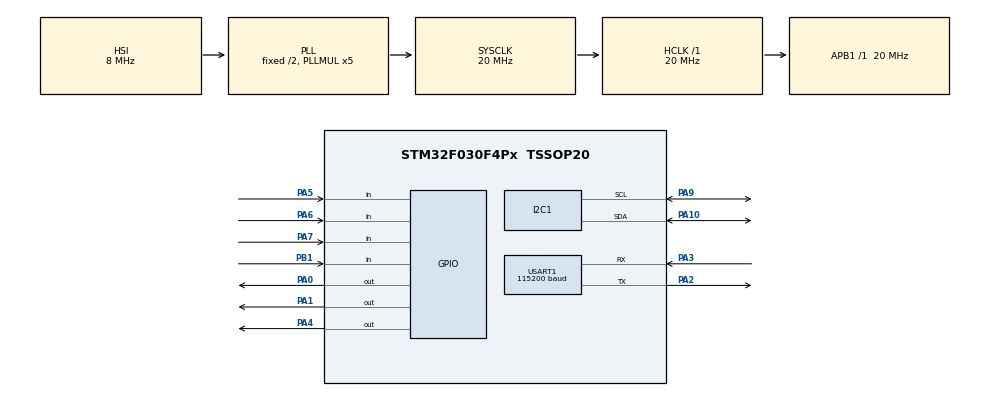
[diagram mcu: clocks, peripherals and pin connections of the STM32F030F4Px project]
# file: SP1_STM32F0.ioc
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I2C1.Timing=0x2000090E
IWDG.Prescaler=IWDG_PRESCALER_8
IWDG.Reload=4000
IWDG.Window=4000
Mcu.Family=STM32F0
Mcu.Name=STM32F030F4Px
Mcu.Package=TSSOP20
NVIC.USART1_IRQn=true\:0\:0\:false\:false\:true
PA0.Signal=GPIO_Output
PA1.Signal=GPIO_Output
PA10.Mode=I2C
PA10.Signal=I2C1_SDA
PA2.Mode=Asynchronous
PA2.Signal=USART1_TX
PA3.Mode=Asynchronous
PA3.Signal=USART1_RX
PA4.Signal=GPIO_Output
PA5.GPIO_PuPd=GPIO_PULLUP
PA5.Signal=GPIO_Input
PA6.GPIO_PuPd=GPIO_PULLUP
PA6.Signal=GPIO_Input
PA7.GPIO_PuPd=GPIO_PULLUP
PA7.Signal=GPIO_Input
PA9.Mode=I2C
PA9.Signal=I2C1_SCL
PB1.GPIO_PuPd=GPIO_PULLUP
PB1.Signal=GPIO_Input
ProjectManager.HeapSize=0x200
ProjectManager.StackSize=0x400
ProjectManager.TargetToolchain=MDK-ARM V5
RCC.AHBFreq_Value=20000000
RCC.APB1Freq_Value=20000000
RCC.APB1TimFreq_Value=20000000
RCC.HCLKFreq_Value=20000000
RCC.PLLMUL=RCC_PLL_MUL5
RCC.SYSCLKFreq_VALUE=20000000
RCC.SYSCLKSource=RCC_SYSCLKSOURCE_PLLCLK
USART1.BaudRate=115200
USART1.VirtualMode-Asynchronous=VM_ASYNC
VP_IWDG_VS_IWDG.Mode=IWDG_Activate
board=SP1_STM32F0

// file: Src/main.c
/**
  ******************************************************************************
  * File Name          : main.c
  * Description        : Main program body
  ******************************************************************************
  ** This notice applies to any and all portions of this file
  * that are not between comment pairs USER CODE BEGIN and
  * USER CODE END. Other portions of this file, whether
  * inserted by the user or by software development tools
  * are owned by their respective copyright owners.
  *
  * COPYRIGHT(c) 2017 STMicroelectronics
  *
  * Redistribution and use in source and binary forms, with or without modification,
  * are permitted provided that the following conditions are met:
  *   1. Redistributions of source code must retain the above copyright notice,
  *      this list of conditions and the following disclaimer.
  *   2. Redistributions in binary form must reproduce the above copyright notice,
  *      this list of conditions and the following disclaimer in the documentation
  *      and/or other materials provided with the distribution.
  *   3. Neither the name of STMicroelectronics nor the names of its contributors
  *      may be used to endorse or promote products derived from this software
  *      without specific prior written permission.
  *
  * THIS SOFTWARE IS PROVIDED BY THE COPYRIGHT HOLDERS AND CONTRIBUTORS "AS IS"
  * AND ANY EXPRESS OR IMPLIED WARRANTIES, INCLUDING, BUT NOT LIMITED TO, THE
  * IMPLIED WARRANTIES OF MERCHANTABILITY AND FITNESS FOR A PARTICULAR PURPOSE ARE
  * DISCLAIMED. IN NO EVENT SHALL THE COPYRIGHT HOLDER OR CONTRIBUTORS BE LIABLE
  * FOR ANY DIRECT, INDIRECT, INCIDENTAL, SPECIAL, EXEMPLARY, OR CONSEQUENTIAL
  * DAMAGES (INCLUDING, BUT NOT LIMITED TO, PROCUREMENT OF SUBSTITUTE GOODS OR
  * SERVICES; LOSS OF USE, DATA, OR PROFITS; OR BUSINESS INTERRUPTION) HOWEVER
  * CAUSED AND ON ANY THEORY OF LIABILITY, WHETHER IN CONTRACT, STRICT LIABILITY,
  * OR TORT (INCLUDING NEGLIGENCE OR OTHERWISE) ARISING IN ANY WAY OUT OF THE USE
  * OF THIS SOFTWARE, EVEN IF ADVISED OF THE POSSIBILITY OF SUCH DAMAGE.
  *
  ******************************************************************************
  */
#include "main.h"
#include "stm32f0xx_hal.h"

/* USER CODE BEGIN Includes */
#include "gpio.h"
#include "hardware.h"
#include "stateMachine.h"
#include "uart.h"

/* USER CODE END Includes */

I2C_HandleTypeDef hi2c1;

IWDG_HandleTypeDef hiwdg;

UART_HandleTypeDef huart1;

/* USER CODE BEGIN PV */
/* Private variables ---------------------------------------------------------*/
uint8_t data = 0;
uint8_t buffer = 0;
/* USER CODE END PV */

void SystemClock_Config(void);
static void MX_GPIO_Init(void);
static void MX_USART1_UART_Init(void);
static void MX_IWDG_Init(void);
static void MX_I2C1_Init(void);

/* USER CODE BEGIN PFP */
/* Private function prototypes -----------------------------------------------*/

/* USER CODE END PFP */

int main(void)
{

    /* MCU Configuration----------------------------------------------------------*/

    /* Reset of all peripherals, Initializes the Flash interface and the Systick. */
    HAL_Init();

    /* Configure the system clock */
    SystemClock_Config();

    /* Initialize all configured peripherals */
    MX_GPIO_Init();
    MX_USART1_UART_Init();
    MX_IWDG_Init();
    MX_I2C1_Init();

    /* USER CODE BEGIN 2 */
    uartBufferInit();
    /* USER CODE END 2 */

    /* Infinite loop */
    /* USER CODE BEGIN WHILE */
    while (1) {
        // Middle
        stateUpdate();
        stateMachine();
        // Watchdog timer value 1s
        HAL_IWDG_Refresh(&hiwdg);

        /* USER CODE END WHILE */

    }
}

/** System Clock Configuration
*/
void SystemClock_Config(void)
{

    RCC_OscInitTypeDef RCC_OscInitStruct;
    RCC_ClkInitTypeDef RCC_ClkInitStruct;
    RCC_PeriphCLKInitTypeDef PeriphClkInit;

    /**Initializes the CPU, AHB and APB busses clocks
    */
    RCC_OscInitStruct.OscillatorType = RCC_OSCILLATORTYPE_HSI | RCC_OSCILLATORTYPE_LSI;
    RCC_OscInitStruct.HSIState = RCC_HSI_ON;
    RCC_OscInitStruct.HSICalibrationValue = 16;
    RCC_OscInitStruct.LSIState = RCC_LSI_ON;
    RCC_OscInitStruct.PLL.PLLState = RCC_PLL_ON;
    RCC_OscInitStruct.PLL.PLLSource = RCC_PLLSOURCE_HSI;
    RCC_OscInitStruct.PLL.PLLMUL = RCC_PLL_MUL5;
    RCC_OscInitStruct.PLL.PREDIV = RCC_PREDIV_DIV1;
    if (HAL_RCC_OscConfig(&RCC_OscInitStruct) != HAL_OK) {
        _Error_Handler(__FILE__, __LINE__);
    }

    /**Initializes the CPU, AHB and APB busses clocks
    */
    RCC_ClkInitStruct.ClockType = RCC_CLOCKTYPE_HCLK | RCC_CLOCKTYPE_SYSCLK
        | RCC_CLOCKTYPE_PCLK1;
    RCC_ClkInitStruct.SYSCLKSource = RCC_SYSCLKSOURCE_PLLCLK;
    RCC_ClkInitStruct.AHBCLKDivider = RCC_SYSCLK_DIV1;
    RCC_ClkInitStruct.APB1CLKDivider = RCC_HCLK_DIV1;

    if (HAL_RCC_ClockConfig(&RCC_ClkInitStruct, FLASH_LATENCY_0) != HAL_OK) {
        _Error_Handler(__FILE__, __LINE__);
    }

    PeriphClkInit.PeriphClockSelection = RCC_PERIPHCLK_USART1 | RCC_PERIPHCLK_I2C1;
    PeriphClkInit.Usart1ClockSelection = RCC_USART1CLKSOURCE_PCLK1;
    PeriphClkInit.I2c1ClockSelection = RCC_I2C1CLKSOURCE_HSI;
    if (HAL_RCCEx_PeriphCLKConfig(&PeriphClkInit) != HAL_OK) {
        _Error_Handler(__FILE__, __LINE__);
    }

    /**Configure the Systick interrupt time
    */
    HAL_SYSTICK_Config(HAL_RCC_GetHCLKFreq() / 1000);

    /**Configure the Systick
    */
    HAL_SYSTICK_CLKSourceConfig(SYSTICK_CLKSOURCE_HCLK);

    /* SysTick_IRQn interrupt configuration */
    HAL_NVIC_SetPriority(SysTick_IRQn, 0, 0);
}

/* I2C1 init function */
static void MX_I2C1_Init(void)
{

    hi2c1.Instance = I2C1;
    hi2c1.Init.Timing = 0x2000090E;
    hi2c1.Init.OwnAddress1 = 0;
    hi2c1.Init.AddressingMode = I2C_ADDRESSINGMODE_7BIT;
    hi2c1.Init.DualAddressMode = I2C_DUALADDRESS_DISABLE;
    hi2c1.Init.OwnAddress2 = 0;
    hi2c1.Init.OwnAddress2Masks = I2C_OA2_NOMASK;
    hi2c1.Init.GeneralCallMode = I2C_GENERALCALL_DISABLE;
    hi2c1.Init.NoStretchMode = I2C_NOSTRETCH_DISABLE;
    if (HAL_I2C_Init(&hi2c1) != HAL_OK) {
        _Error_Handler(__FILE__, __LINE__);
    }

    /**Configure Analogue filter
    */
    if (HAL_I2CEx_ConfigAnalogFilter(&hi2c1, I2C_ANALOGFILTER_ENABLE) != HAL_OK) {
        _Error_Handler(__FILE__, __LINE__);
    }

    /**Configure Digital filter
    */
    if (HAL_I2CEx_ConfigDigitalFilter(&hi2c1, 0) != HAL_OK) {
        _Error_Handler(__FILE__, __LINE__);
    }
}

/* IWDG init function */
static void MX_IWDG_Init(void)
{

    hiwdg.Instance = IWDG;
    hiwdg.Init.Prescaler = IWDG_PRESCALER_8;
    hiwdg.Init.Window = 4000;
    hiwdg.Init.Reload = 4000;
    if (HAL_IWDG_Init(&hiwdg) != HAL_OK) {
        _Error_Handler(__FILE__, __LINE__);
    }
}

/* USART1 init function */
static void MX_USART1_UART_Init(void)
{

    huart1.Instance = USART1;
    huart1.Init.BaudRate = 115200;
    huart1.Init.WordLength = UART_WORDLENGTH_8B;
    huart1.Init.StopBits = UART_STOPBITS_1;
    huart1.Init.Parity = UART_PARITY_NONE;
    huart1.Init.Mode = UART_MODE_TX_RX;
    huart1.Init.HwFlowCtl = UART_HWCONTROL_NONE;
    huart1.Init.OverSampling = UART_OVERSAMPLING_16;
    huart1.Init.OneBitSampling = UART_ONE_BIT_SAMPLE_DISABLE;
    huart1.AdvancedInit.AdvFeatureInit = UART_ADVFEATURE_NO_INIT;
    if (HAL_UART_Init(&huart1) != HAL_OK) {
        _Error_Handler(__FILE__, __LINE__);
    }
}

/** Configure pins as
        * Analog
        * Input
        * Output
        * EVENT_OUT
        * EXTI
*/
static void MX_GPIO_Init(void)
{

    GPIO_InitTypeDef GPIO_InitStruct;

    /* GPIO Ports Clock Enable */
    __HAL_RCC_GPIOA_CLK_ENABLE();
    __HAL_RCC_GPIOB_CLK_ENABLE();

    /*Configure GPIO pin Output Level */
    HAL_GPIO_WritePin(GPIOA, GPIO_PIN_0 | GPIO_PIN_1 | GPIO_PIN_4, GPIO_PIN_RESET);

    /*Configure GPIO pins : PA0 PA1 PA4 */
    GPIO_InitStruct.Pin = GPIO_PIN_0 | GPIO_PIN_1 | GPIO_PIN_4;
    GPIO_InitStruct.Mode = GPIO_MODE_OUTPUT_PP;
    GPIO_InitStruct.Pull = GPIO_NOPULL;
    GPIO_InitStruct.Speed = GPIO_SPEED_FREQ_LOW;
    HAL_GPIO_Init(GPIOA, &GPIO_InitStruct);

    /*Configure GPIO pins : PA5 PA6 PA7 */
    GPIO_InitStruct.Pin = GPIO_PIN_5 | GPIO_PIN_6 | GPIO_PIN_7;
    GPIO_InitStruct.Mode = GPIO_MODE_INPUT;
    GPIO_InitStruct.Pull = GPIO_PULLUP;
    HAL_GPIO_Init(GPIOA, &GPIO_InitStruct);

    /*Configure GPIO pin : PB1 */
    GPIO_InitStruct.Pin = GPIO_PIN_1;
    GPIO_InitStruct.Mode = GPIO_MODE_INPUT;
    GPIO_InitStruct.Pull = GPIO_PULLUP;
    HAL_GPIO_Init(GPIOB, &GPIO_InitStruct);
}

void _Error_Handler(char* file, int line)
{
    while (1) {
    }
}

/************************ (C) COPYRIGHT STMicroelectronics *****END OF FILE****/
